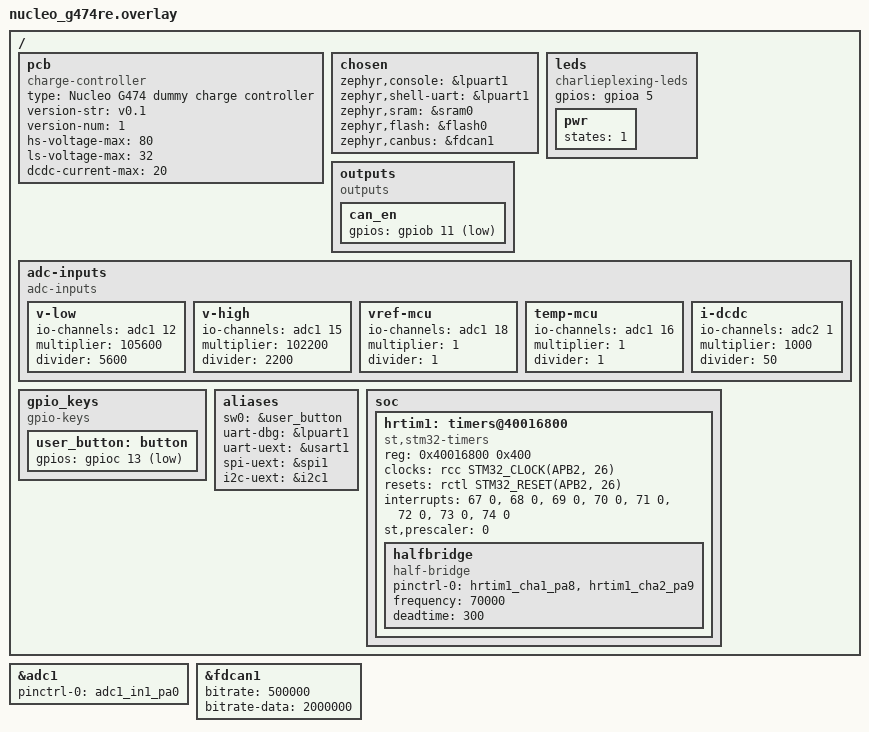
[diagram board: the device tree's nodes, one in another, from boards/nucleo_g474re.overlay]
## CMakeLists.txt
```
# Copyright (c) The Libre Solar Project Contributors
# SPDX-License-Identifier: Apache-2.0

cmake_minimum_required(VERSION 3.13.1)
find_package(Zephyr REQUIRED HINTS $ENV{ZEPHYR_BASE})

project(libre_solar_charge_controller)

add_subdirectory(src)

# determine git tag and commit hash for automatic firmware versioning
find_package(Git)
if(GIT_FOUND)
    execute_process(
        COMMAND ${GIT_EXECUTABLE} describe --long --dirty --tags
        OUTPUT_VARIABLE FIRMWARE_VERSION_ID
        OUTPUT_STRIP_TRAILING_WHITESPACE)
else()
    set(FIRMWARE_VERSION_ID "unknown")
endif()
add_definitions(-DFIRMWARE_VERSION_ID="${FIRMWARE_VERSION_ID}")
```

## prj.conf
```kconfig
# Main application configuration (overrides board-specific settings)

# only very small heap necessary for malloc in printf statements with %f
CONFIG_HEAP_MEM_POOL_SIZE=256

CONFIG_CPP=y
CONFIG_REQUIRES_FULL_LIBCPP=y

CONFIG_NEWLIB_LIBC=y
CONFIG_NEWLIB_LIBC_NANO=y
CONFIG_NEWLIB_LIBC_FLOAT_PRINTF=y

CONFIG_WATCHDOG=y
CONFIG_WDT_DISABLE_AT_BOOT=y
CONFIG_TASK_WDT=y
CONFIG_THREAD_NAME=y

CONFIG_REBOOT=y

CONFIG_HWINFO=y

CONFIG_CRC=y

CONFIG_CONSOLE_SUBSYS=y
CONFIG_CONSOLE_GETCHAR=y

# Use minimal logging by default to save memory for STM32F0 with little RAM
CONFIG_LOG=y
CONFIG_LOG_MODE_MINIMAL=y

CONFIG_THINGSET=y
CONFIG_THINGSET_SDK=y
CONFIG_THINGSET_STORAGE=y
CONFIG_THINGSET_SERIAL=y
CONFIG_THINGSET_STORAGE_DATA_VERSION=6
CONFIG_THINGSET_NODE_NAME="Libre Solar MPPT"

# Must be lower than LED thread to avoid flickering in boards with charlieplexing
CONFIG_THINGSET_SDK_THREAD_PRIORITY=6

# Uncomment to disable regular data publication on ThingSet serial at startup
#CONFIG_THINGSET_REPORTING_LIVE_ENABLE_PRESET=n

# Uncomment to enable I2C OLED display in UEXT connector
#CONFIG_UEXT_OLED_DISPLAY=y

# Select initial battery configuration: GEL (default), FLOODED, AGM, LFP, NMC or NMC_HV
#CONFIG_BAT_TYPE_???=y

# Change number of cells considering selected type (12V/24V battery by default if not set)
#CONFIG_BAT_NUM_CELLS=?
```

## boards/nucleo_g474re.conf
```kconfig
# SPDX-License-Identifier: Apache-2.0

CONFIG_FLASH=y
CONFIG_FLASH_PAGE_LAYOUT=y
CONFIG_FLASH_LOG_LEVEL_WRN=y

CONFIG_NVS=y
CONFIG_NVS_LOG_LEVEL_WRN=y
```

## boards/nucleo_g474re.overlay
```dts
/*
 * Copyright (c) The Libre Solar Project Contributors
 *
 * SPDX-License-Identifier: Apache-2.0
 *
 * This is a dummy charge controller board for testing new features using the STM32G474 MCU
 *
 * IMPORTANT: You have to remove the VREF jumper on the Nucleo board to make it work. Otherwise
 *            the MCU will get stuck while trying to generate a reference voltage at VREF+ pin.
 */

/ {
	/* delete conflicting nodes from Zephyr board */
	/delete-node/ leds;
	/delete-node/ aliases;

	pcb {
		compatible = "charge-controller";

		type = "Nucleo G474 dummy charge controller";
		version-str = "v0.1";
		version-num = <1>;

		hs-voltage-max = <80>;
		ls-voltage-max = <32>;
		dcdc-current-max = <20>;
	};

	chosen {
		zephyr,console = &lpuart1;
		zephyr,shell-uart = &lpuart1;
		zephyr,sram = &sram0;
		zephyr,flash = &flash0;
		zephyr,canbus = &fdcan1;
	};

	leds {
		compatible = "charlieplexing-leds";
		gpios = <&gpioa 5 GPIO_ACTIVE_HIGH>;

		pwr {
			states = <1>;
		};
	};

	outputs {
		compatible = "outputs";

		can_en {
			gpios = <&gpiob 11 GPIO_ACTIVE_LOW>;
		};
	};

	adc-inputs {
		compatible = "adc-inputs";

		v-low {
			io-channels = <&adc1 12>;
			multiplier = <105600>;
			divider = <5600>;
		};

		v-high {
			io-channels = <&adc1 15>;
			multiplier = <102200>;
			divider = <2200>;
		};

		vref-mcu {
			io-channels = <&adc1 18>;
			multiplier = <1>;
			divider = <1>;
		};

		temp-mcu {
			io-channels = <&adc1 16>;
			multiplier = <1>;
			divider = <1>;
		};

		i-dcdc {
			io-channels = <&adc2 1>;
			// amp gain: 25, resistor: 2 mOhm
			multiplier = <1000>;	// 1000
			divider = <50>;	// 2*25
		};
	};

	gpio_keys {
		compatible = "gpio-keys";
		user_button: button {
			gpios = <&gpioc 13 GPIO_ACTIVE_LOW>;
		};
	};

	aliases {
		sw0 = &user_button;
		uart-dbg = &lpuart1;
		uart-uext = &usart1;
		spi-uext = &spi1;
		i2c-uext = &i2c1;
	};

	soc {
		hrtim1: timers@40016800 {
			compatible = "st,stm32-timers";
			reg = <0x40016800 0x400>;
			clocks = <&rcc STM32_CLOCK(APB2, 26)>;
			resets = <&rctl STM32_RESET(APB2, 26)>;
			interrupts = <67 0>, <68 0>, <69 0>, <70 0>,
				     <71 0>, <72 0>, <73 0>, <74 0>;
			interrupt-names = "master", "tima", "timb", "timc",
					  "timd", "time", "flt", "timf";
			st,prescaler = <0>;
			status = "disabled";
		};
	};
};

&hrtim1 {
	status = "okay";

	halfbridge: halfbridge {
		compatible = "half-bridge";
		pinctrl-0 = <&hrtim1_cha1_pa8 &hrtim1_cha2_pa9>;
		pinctrl-names = "default";
		frequency = <70000>;
		deadtime = <300>;
	};
};

/*
// alternative to HRTIM
&timers1 {
	status = "okay";

	halfbridge: halfbridge {
		compatible = "half-bridge";
		pinctrl-0 = <&tim1_ch1_pa8 &tim1_ch1n_pb13>;
		pinctrl-names = "default";
		frequency = <70000>;
		deadtime = <300>;
	};
};
*/

&adc1 {
	pinctrl-0 = <&adc1_in1_pa0>;
	pinctrl-names = "default";
	status = "okay";
};

&fdcan1 {
	bitrate = <500000>;
	bitrate-data = <2000000>;
	status = "okay";
};
```

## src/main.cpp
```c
/*
 * Copyright (c) The Libre Solar Project Contributors
 *
 * SPDX-License-Identifier: Apache-2.0
 */

#ifndef UNIT_TEST

#include <stdio.h>
#include <zephyr/device.h>
#include <zephyr/drivers/gpio.h>
#include <zephyr/kernel.h>
#include <zephyr/task_wdt/task_wdt.h>

#include "helper.h"
#include "setup.h"

#include "bat_charger.h"   // battery settings and charger state machine
#include "daq.h"           // ADC using DMA and conversion to measurement values
#include "data_objects.h"  // for access to internal data via ThingSet
#include "dcdc.h"          // DC/DC converter control (hardware independent)
#include "device_status.h" // log data (error memory, min/max measurements, etc.)
#include "half_bridge.h"   // PWM generation for DC/DC converter
#include "hardware.h" // hardware-related functions like load switch, LED control, watchdog, etc.
#include "leds.h"     // LED switching using charlieplexing
#include "load.h"     // load and USB output management
#if BOARD_HAS_PWM_PORT
#include "pwm_switch.h" // PWM charge controller
#endif

int main(void)
{
    printf("Hardware: Libre Solar %s (%s)\n", DT_PROP(DT_PATH(pcb), type),
           DT_PROP(DT_PATH(pcb), version_str));
    printf("Firmware: %s\n", FIRMWARE_VERSION_ID);

    task_wdt_init(DEVICE_DT_GET_OR_NULL(DT_NODELABEL(iwdg)));

    setup();

    battery_conf_init(&bat_conf, CONFIG_BAT_TYPE, CONFIG_BAT_NUM_CELLS, CONFIG_BAT_CAPACITY_AH);
    battery_conf_overwrite(&bat_conf, &bat_conf_user); // initialize conf_user with same values

#if BOARD_HAS_DCDC
    daq_set_hv_limit(DT_PROP(DT_PATH(pcb), hs_voltage_max));
#endif

#if CONFIG_HV_TERMINAL_SOLAR || CONFIG_LV_TERMINAL_SOLAR || CONFIG_PWM_TERMINAL_SOLAR
    solar_terminal.init_solar();
#endif

#if CONFIG_HV_TERMINAL_NANOGRID
    grid_terminal.init_nanogrid();
#endif

    // make sure loaded configuration is valid
    data_objects_init();

    // Data Acquisition (DAQ) setup
    daq_setup();

    charger.detect_num_batteries(&bat_conf); // check if we have 24V instead of 12V system
    charger.init_terminal(&bat_conf);

#if BOARD_HAS_LOAD_OUTPUT
    load.set_voltage_limits(bat_conf.load_disconnect_voltage, bat_conf.load_reconnect_voltage,
                            bat_conf.absolute_max_voltage);
#endif

#if BOARD_HAS_USB_OUTPUT
    usb_pwr.set_voltage_limits(bat_conf.load_disconnect_voltage - 0.1f, // keep on longer than load
                               bat_conf.load_reconnect_voltage, bat_conf.absolute_max_voltage);
#endif

    // wait until all threads are spawned before activating the watchdog
    k_sleep(K_MSEC(2500));

    int64_t t_start = k_uptime_get();

    while (true) {
        // loop runs exactly once per second and includes slow control tasks and energy calculation

        charger.discharge_control(&bat_conf);
        charger.charge_control(&bat_conf);

// energy + soc calculation must be called exactly once per second
#if BOARD_HAS_DCDC
        if (dcdc.state != DCDC_CONTROL_OFF) {
            hv_terminal.energy_balance();
        }
#endif

#if BOARD_HAS_PWM_PORT
        if (pwm_switch.active() == 1) {
            pwm_switch.energy_balance();
        }
#endif

        lv_terminal.energy_balance();

#if BOARD_HAS_LOAD_OUTPUT
        if (load.state == 1) {
            load.energy_balance();
        }
#endif

        dev_stat.update_energy();
        dev_stat.update_min_max_values();
        charger.update_soc(&bat_conf);

#if CONFIG_HS_MOSFET_FAIL_SAFE_PROTECTION && BOARD_HAS_DCDC
        if (dev_stat.has_error(ERR_DCDC_HS_MOSFET_SHORT)) {
            dcdc.fuse_destruction();
        }
#endif

        leds_update_1s();

#if BOARD_HAS_LOAD_OUTPUT
        leds_update_soc(charger.soc, flags_check(&load.error_flags, ERR_LOAD_SHEDDING));
#else
        leds_update_soc(charger.soc, false);
#endif

        t_start += 1000;
        k_sleep(K_TIMEOUT_ABS_MS(t_start));
    }
}

void control_thread()
{
    int wdt_channel = task_wdt_add(200, task_wdt_callback, (void *)k_current_get());

    while (true) {
        // control loop runs at approx. 10 Hz

        bool charging = false;

        task_wdt_feed(wdt_channel);

        // convert ADC readings to meaningful measurement values
        daq_update();

        // alerts should trigger only for transients, so update based on actual voltage
        daq_set_lv_limits(lv_terminal.bus->voltage * 1.2F, lv_terminal.bus->voltage * 0.8F);

        lv_terminal.update_bus_current_margins();

#if BOARD_HAS_PWM_PORT
        pwm_switch.control();
        charging |= pwm_switch.active();
#endif

#if BOARD_HAS_DCDC
        hv_terminal.update_bus_current_margins();
        dcdc.control(); // control of DC/DC including MPPT algorithm
        charging |= half_bridge_enabled();
#endif

        leds_set_charging(charging);

#if BOARD_HAS_LOAD_OUTPUT
        load.control();
#endif

#if BOARD_HAS_USB_OUTPUT
        usb_pwr.control();
#endif

        k_sleep(K_MSEC(100));
    }
}

// 2s delay for control thread as a safety feature: be able to re-flash before starting
// priority is set to -1 (=cooperative) to have higher priority than other threads incl. main
K_THREAD_DEFINE(control_thread_id, 1024, control_thread, NULL, NULL, NULL, -1, 0, 2000);

#endif // UNIT_TEST
```

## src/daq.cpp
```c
/*
 * Copyright (c) The Libre Solar Project Contributors
 *
 * SPDX-License-Identifier: Apache-2.0
 */

#include "daq.h"

#include <zephyr/kernel.h>

#include <zephyr/logging/log.h>
LOG_MODULE_REGISTER(daq, CONFIG_DAQ_LOG_LEVEL);

#include <assert.h>
#include <math.h> // log for thermistor calculation

#include "mcu.h"
#include "setup.h"

// typical value for Semitec 103AT-5 thermistor: 3435
#define NTC_BETA_VALUE 3435

// filter parameter c for additional battery voltage and current low-pass filter
// c = dt / (tau + dt) = 0.1s / (10s + 0.1s)
#define HV_BUS_VOLTAGE_FILTER_CONST      0.0099F
#define LV_BUS_VOLTAGE_FILTER_CONST      0.0099F
#define LV_TERMINAL_CURRENT_FILTER_CONST 0.0099F
#define PWM_CURRENT_FILTER_CONST         0.0625F // 1.5 seconds

#if BOARD_HAS_DCDC
static uint16_t dcdc_current_offset_raw;
#endif
#if BOARD_HAS_PWM_PORT
static uint16_t pwm_current_offset_raw;
#endif
#if BOARD_HAS_LOAD_OUTPUT
static uint16_t load_current_offset_raw;
#endif

// 16-bit ADC raw readings (actually left-aligned 12-bit, i.e. left-shifted by 4 bits)
volatile uint16_t adc_readings[NUM_ADC_CH] = {};

// filtered raw readings left-shifted by additional adc_filter_const[channel] bits
volatile uint32_t adc_filtered[NUM_ADC_CH] = {};

static volatile AdcAlert adc_alerts_upper[NUM_ADC_CH] = {};
static volatile AdcAlert adc_alerts_lower[NUM_ADC_CH] = {};

/*
 * Channel-specific ADC filter constant from devicetree
 *
 * multiplier = 1/(2^adc_filter_const[channel])
 */
#define ADC_FILTER_CONST(node_id) DT_PROP(node_id, filter_const),
static const uint8_t adc_filter_const[NUM_ADC_CH] = { DT_FOREACH_CHILD(DT_PATH(adc_inputs),
                                                                       ADC_FILTER_CONST) };

/**
 * Average value for ADC channel
 *
 * @param channel valid ADC channel position using ADC_POS() macro
 */
static inline uint32_t adc_raw_filtered(uint32_t channel)
{
    return adc_filtered[channel] >> adc_filter_const[channel];
}

/**
 * Measured current/voltage for ADC channel after average and scaling
 *
 * @param channel valid ADC channel position using ADC_POS() macro
 * @param vref reference voltage in millivolts
 * @param offset offset added to raw ADC value before applying gain
 *
 * @return scaled final value in volts/amps
 */
static inline float adc_scaled(uint32_t channel, int32_t vref, const float gain, int32_t offset = 0)
{
    return adc_raw_to_voltage(adc_raw_filtered(channel) - offset, vref) * gain;
}

static inline float ntc_temp(uint32_t channel, int32_t vref, float ntc_series_resistor)
{
    /** \todo Improved (faster) temperature calculation:
       https://www.embeddedrelated.com/showarticle/91.php
    */

    // voltage read by ADC (mV)
    float v_temp = adc_raw_to_voltage(adc_raw_filtered(channel), vref) * 1000;

    // resistance of NTC (Ohm)
    float rts = ntc_series_resistor * v_temp / (vref - v_temp);

    return 1.0f / (1.0f / (273.15f + 25.0f) + 1.0f / (float)NTC_BETA_VALUE * logf(rts / 10000.0f))
           - 273.15f; // °C
}

void calibrate_current_sensors()
{
#if BOARD_HAS_DCDC
    dcdc_current_offset_raw = adc_raw_filtered(ADC_POS(i_dcdc));
#endif
#if BOARD_HAS_PWM_PORT
    pwm_current_offset_raw = adc_raw_filtered(ADC_POS(i_pwm));
#endif
#if BOARD_HAS_LOAD_OUTPUT
    load_current_offset_raw = adc_raw_filtered(ADC_POS(i_load));
#endif
}

void adc_update_value(unsigned int pos)
{
#if BOARD_HAS_PWM_PORT
    // only read input voltage and current when switch is on or permanently off
    if ((pos != ADC_POS(v_pwm) && pos != ADC_POS(i_pwm)) || pwm_switch.signal_high()
        || pwm_switch.active() == false)
#endif
    {
        /*
         * Low-pass filtering of ADC raw readings
         * (see also: http://techteach.no/simview/lowpass_filter/doc/filter_algorithm.pdf)
         *
         * y(n) = c * x(n) + (1 - c) * y(n-1) with filter constant c = 1/(2^adc_filter_const[pos])
         *
         * Remarks regarding below implementation optimized for efficiency:
         *
         * 1. adc_readings has different fixed-point math format, so that it would have to be
         *    aligned with << adc_filter_const[pos] before calculation. Not aligning it is
         *    equivalent to multiplication with c:
         *    adc_readings[pos] == c * (adc_readings[pos] << adc_filter_const[pos])
         *
         * 2. c * adc_filtered[pos] == adc_filtered[pos] >> adc_filter_const[pos]
         */
        adc_filtered[pos] = (uint32_t)adc_readings[pos] + adc_filtered[pos]
                            - (adc_filtered[pos] >> adc_filter_const[pos]);
    }

    // check upper alerts
    adc_alerts_upper[pos].debounce_ms++;
    if (adc_alerts_upper[pos].callback != NULL && adc_readings[pos] >= adc_alerts_upper[pos].limit)
    {
        if (adc_alerts_upper[pos].debounce_ms > 1) {
            // create function pointer and call function
            adc_alerts_upper[pos].callback();
        }
    }
    else if (adc_alerts_upper[pos].debounce_ms > 0) {
        // reset debounce ms counter only if already close to triggering to allow setting negative
        // values to specify a one-time inhibit delay
        adc_alerts_upper[pos].debounce_ms = 0;
    }

    // same for lower alerts
    adc_alerts_lower[pos].debounce_ms++;
    if (adc_alerts_lower[pos].callback != NULL && adc_readings[pos] <= adc_alerts_lower[pos].limit)
    {
        if (adc_alerts_lower[pos].debounce_ms > 1) {
            adc_alerts_lower[pos].callback();
        }
    }
    else if (adc_alerts_lower[pos].debounce_ms > 0) {
        adc_alerts_lower[pos].debounce_ms = 0;
    }
}

void daq_update()
{
    int vref = VREF;

    // calculate lower voltage first, as it is needed for PWM terminal voltage calculation
    lv_bus.voltage = adc_scaled(ADC_POS(v_low), vref, ADC_GAIN(v_low));

    if (lv_bus.voltage_filtered != 0.0F) {
        lv_bus.voltage_filtered = LV_BUS_VOLTAGE_FILTER_CONST * lv_bus.voltage
                                  + (1.0F - LV_BUS_VOLTAGE_FILTER_CONST) * lv_bus.voltage_filtered;
    }
    else {
        // initialize properly at startup
        lv_bus.voltage_filtered = lv_bus.voltage;
    }

#if BOARD_HAS_DCDC
    hv_bus.voltage = adc_scaled(ADC_POS(v_high), vref, ADC_GAIN(v_high));

    if (hv_bus.voltage_filtered != 0.0F) {
        hv_bus.voltage_filtered = HV_BUS_VOLTAGE_FILTER_CONST * hv_bus.voltage
                                  + (1.0F - HV_BUS_VOLTAGE_FILTER_CONST) * hv_bus.voltage_filtered;
    }
    else {
        // initialize properly at startup
        hv_bus.voltage_filtered = hv_bus.voltage;
    }
#endif

#if BOARD_HAS_PWM_PORT
    pwm_switch.ext_voltage =
        lv_bus.voltage - adc_scaled(ADC_POS(v_pwm), vref, ADC_GAIN(v_pwm), ADC_OFFSET(v_pwm));
#endif

#if BOARD_HAS_LOAD_OUTPUT
    load.current = adc_scaled(ADC_POS(i_load), vref, ADC_GAIN(i_load), load_current_offset_raw);
    float load_current = load.current;
#else
    float load_current = 0; // value used below, so we still need to define the variable
#endif

    float lv_terminal_current = -load_current;

#if BOARD_HAS_PWM_PORT
    // current multiplied with PWM duty cycle for PWM charger to get avg current for correct power
    // calculation
    pwm_switch.current =
        -pwm_switch.get_duty_cycle()
        * adc_scaled(ADC_POS(i_pwm), vref, ADC_GAIN(i_pwm), pwm_current_offset_raw);
    pwm_switch.current_filtered = PWM_CURRENT_FILTER_CONST * pwm_switch.current
                                  + (1.0F - PWM_CURRENT_FILTER_CONST) * pwm_switch.current_filtered;

    lv_terminal_current -= pwm_switch.current;

    pwm_switch.power = pwm_switch.bus->voltage * pwm_switch.current;
#endif

#if BOARD_HAS_DCDC
    dcdc.inductor_current =
        adc_scaled(ADC_POS(i_dcdc), vref, ADC_GAIN(i_dcdc), dcdc_current_offset_raw);

    lv_terminal_current += dcdc.inductor_current;

    hv_terminal.current =
        -dcdc.inductor_current * lv_terminal.bus->voltage / hv_terminal.bus->voltage;

    dcdc.power = dcdc.lvb->voltage * dcdc.inductor_current;
    hv_terminal.power = hv_terminal.bus->voltage * hv_terminal.current;
#endif
    lv_terminal.current = lv_terminal_current;
    lv_terminal.power = lv_terminal.bus->voltage * lv_terminal.current;

    lv_terminal.current_filtered =
        LV_TERMINAL_CURRENT_FILTER_CONST * lv_terminal.current
        + (1.0F - LV_TERMINAL_CURRENT_FILTER_CONST) * lv_terminal.current_filtered;

#if BOARD_HAS_LOAD_OUTPUT
    load.power = load.bus->voltage * load.current;
#endif

#if BOARD_HAS_TEMP_BAT
    // battery temperature calculation
    float bat_temp = ntc_temp(ADC_POS(temp_bat), vref, ADC_GAIN(temp_bat));

    if (bat_temp > -50) {
        // external sensor connected: take measured value
        charger.bat_temperature = bat_temp;
        charger.ext_temp_sensor = true;
    }
    else {
        // no external sensor: assume typical room temperature
        charger.bat_temperature = 25;
        charger.ext_temp_sensor = false;
    }
#endif

#if BOARD_HAS_TEMP_FETS
    dcdc.temp_mosfets = ntc_temp(ADC_POS(temp_fets), vref, ADC_GAIN(temp_fets));
#endif

    // internal MCU temperature (calibrated using 12-bit right-aligned readings)
    uint16_t adcval = (adc_raw_filtered(ADC_POS(temp_mcu)) >> 4) * vref / VREFINT_VALUE;
    dev_stat.internal_temp = (TSENSE_CAL2_VALUE - TSENSE_CAL1_VALUE) / (TSENSE_CAL2 - TSENSE_CAL1)
                                 * (adcval - TSENSE_CAL1)
                             + TSENSE_CAL1_VALUE;

    if (dev_stat.internal_temp > 80) {
        dev_stat.set_error(ERR_INT_OVERTEMP);
    }
    else if (dev_stat.internal_temp < 70 && (dev_stat.has_error(ERR_INT_OVERTEMP))) {
        // remove error flag with hysteresis of 10°C
        dev_stat.clear_error(ERR_INT_OVERTEMP);
    }
    // else: keep previous setting
}

void lv_overvoltage_alert()
{
    // disable any sort of input
#if BOARD_HAS_DCDC
    dcdc.stop();
#endif
#if BOARD_HAS_PWM_PORT
    pwm_switch.stop();
#endif
    // do not use enter_state function, as we don't want to wait entire recharge delay
    charger.state = CHG_STATE_IDLE;

    dev_stat.set_error(ERR_BAT_OVERVOLTAGE);

    LOG_ERR("Low-side overvoltage alert, ADC reading: %d limit: %d\n", adc_readings[ADC_POS(v_low)],
            adc_alerts_upper[ADC_POS(v_low)].limit);
}

void lv_undervoltage_alert()
{
#if BOARD_HAS_LOAD_OUTPUT
    // the battery undervoltage must have been caused by a load current peak
    load.stop(ERR_LOAD_VOLTAGE_DIP);
#endif

    LOG_ERR("Low-side undervoltage alert, ADC reading: %d limit: %d\n",
            adc_readings[ADC_POS(v_low)], adc_alerts_lower[ADC_POS(v_low)].limit);
}

#if BOARD_HAS_DCDC
void hv_overvoltage_alert()
{
    dcdc.stop();

    // do not use enter_state function, as we don't want to wait entire recharge delay
    charger.state = CHG_STATE_IDLE;

    dev_stat.set_error(ERR_DCDC_HS_OVERVOLTAGE);

    LOG_ERR("High-side overvoltage alert, ADC reading: %d limit: %d\n",
            adc_readings[ADC_POS(v_high)], adc_alerts_upper[ADC_POS(v_high)].limit);
}
#endif

void adc_upper_alert_inhibit(int adc_pos, int timeout_ms)
{
    // set negative value so that we get a final debouncing of this timeout + the original
    // delay in the alert function (currently only waiting for 2 samples = 2 ms)
    adc_alerts_upper[adc_pos].debounce_ms = -timeout_ms;
}

uint16_t adc_raw_clamp(float scale, float limit)
{
    // even if we have a higher voltage limit, we must limit it
    // to the max value the ADC will be able to deliver
    const float limit_scaled = limit * scale;
    return limit_scaled > (float)UINT16_MAX ? UINT16_MAX : (uint16_t)(limit_scaled);
}

void daq_set_lv_limits(float lv_overvoltage, float lv_undervoltage)
{
    float scale = (((4096 << 4) * 1000) / ADC_GAIN(v_low)) / (float)VREF;

    // LV side (battery) overvoltage alert
    adc_alerts_upper[ADC_POS(v_low)].limit = adc_raw_clamp(scale, lv_overvoltage);
    adc_alerts_upper[ADC_POS(v_low)].callback = lv_overvoltage_alert;

    // LV side (battery) undervoltage alert
    adc_alerts_lower[ADC_POS(v_low)].limit = adc_raw_clamp(scale, lv_undervoltage);
    adc_alerts_lower[ADC_POS(v_low)].callback = lv_undervoltage_alert;
}

#if BOARD_HAS_DCDC
void daq_set_hv_limit(float hv_overvoltage)
{
    float scale = (((4096 << 4) * 1000) / ADC_GAIN(v_high)) / (float)VREF;

    // HV side (solar/grid) overvoltage alert
    adc_alerts_upper[ADC_POS(v_high)].limit = adc_raw_clamp(scale, hv_overvoltage);
    adc_alerts_upper[ADC_POS(v_high)].callback = hv_overvoltage_alert;
}
#endif

#if !defined(CONFIG_SOC_FAMILY_STM32)

#include "daq_stub.h"

void prepare_adc_readings(AdcValues values)
{
    adc_readings[ADC_POS(vref_mcu)] = (uint16_t)(1.224 / 3.3 * 4096) << 4;
    adc_readings[ADC_POS(v_high)] =
        (uint16_t)((values.solar_voltage / ADC_GAIN(v_high)) / 3.3f * 4096) << 4;
    adc_readings[ADC_POS(v_low)] =
        (uint16_t)((values.battery_voltage / ADC_GAIN(v_low)) / 3.3f * 4096) << 4;
    adc_readings[ADC_POS(i_dcdc)] =
        (uint16_t)((values.dcdc_current / ADC_GAIN(i_dcdc)) / 3.3f * 4096) << 4;
    adc_readings[ADC_POS(i_load)] =
        (uint16_t)((values.load_current / ADC_GAIN(i_load)) / 3.3f * 4096) << 4;
}

void prepare_adc_filtered()
{
    // initialize also filtered values
    for (int i = 0; i < NUM_ADC_CH; i++) {
        adc_filtered[i] = adc_readings[i] << adc_filter_const[i];
    }
}

void clear_adc_filtered()
{
    // initialize also filtered values
    for (int i = 0; i < NUM_ADC_CH; i++) {
        adc_filtered[i] = 0;
    }
}
uint32_t get_adc_filtered(uint32_t channel)
{
    return adc_raw_filtered(channel);
}

#endif /* UNIT_TEST */
```

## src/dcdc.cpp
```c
/*
 * Copyright (c) The Libre Solar Project Contributors
 *
 * SPDX-License-Identifier: Apache-2.0
 */

#include "dcdc.h"

#include <zephyr/kernel.h>

#include <zephyr/device.h>
#include <zephyr/drivers/gpio.h>

#include <math.h> // for fabs function
#include <stdio.h>
#include <stdlib.h> // for min/max function

#include "device_status.h"
#include "half_bridge.h"
#include "helper.h"
#include "setup.h"

#include <thingset.h>
#include <thingset/sdk.h>
#include <thingset/storage.h>

LOG_MODULE_REGISTER(dcdc, CONFIG_DCDC_LOG_LEVEL);

#if BOARD_HAS_DCDC

#define BUCK_DUTY_POWER_DECREASE (-1)
#define BUCK_DUTY_POWER_INCREASE (1)

#define BOOST_DUTY_POWER_DECREASE (1)
#define BOOST_DUTY_POWER_INCREASE (-1)

#ifdef CONFIG_SOC_SERIES_STM32G4X
#define DUTY_STEP_SIZE (3) // increased step size for fast microcontroller
#else
#define DUTY_STEP_SIZE (1) // single minimum step for other microcontrollers
#endif

#if DT_NODE_EXISTS(DT_CHILD(DT_PATH(outputs), hv_out))
#define HV_OUT_NODE DT_CHILD(DT_PATH(outputs), hv_out)
#endif

extern DeviceStatus dev_stat;

Dcdc::Dcdc(DcBus *high, DcBus *low, DcdcOperationMode op_mode)
{
    hvb = high;
    lvb = low;
    mode = op_mode;
    enable = true;
    state = DCDC_CONTROL_OFF;
    inductor_current_max = DT_PROP(DT_PATH(pcb), dcdc_current_max);
    hs_voltage_max = DT_PROP(DT_PATH(pcb), hs_voltage_max);
    ls_voltage_max = DT_PROP(DT_PATH(pcb), ls_voltage_max);
    ls_voltage_min = 9.0;
    output_power_min = 1; // switch off if power < 1 W
    restart_interval = 60;
    off_timestamp = -10000; // start immediately

    // lower duty limit might have to be adjusted dynamically depending on LS voltage
    half_bridge_init(DT_PROP(DT_INST(0, half_bridge), frequency) / 1000,
                     DT_PROP(DT_INST(0, half_bridge), deadtime), 12 / hs_voltage_max, 0.97);
}

void Dcdc::perturb_observe_buck()
{
    if (power >= output_power_min) {
        power_good_timestamp = uptime();
    }

    if ((uptime() - power_good_timestamp > 10 || power < -10.0f) && mode != DCDC_MODE_AUTO) {
        // switch off after 10s low power or negative power (if not in nanogrid mode)
        pwm_direction = 0;
    }
    else if (lvb->voltage > lvb->sink_control_voltage()) {
        state = DCDC_CONTROL_CV_LS;
        pwm_direction = BUCK_DUTY_POWER_DECREASE;
    }
    else if (lvb->sink_current_margin < 0 || inductor_current > inductor_current_max) {
        state = DCDC_CONTROL_CC_LS;
        pwm_direction = BUCK_DUTY_POWER_DECREASE;
    }
    else if (hvb->src_current_margin > 0) {
        state = DCDC_CONTROL_CC_HS;
        pwm_direction = BUCK_DUTY_POWER_DECREASE;
    }
    else if (hvb->voltage < hvb->src_control_voltage() && power > output_power_min) {
        // input voltage below limit
        state = DCDC_CONTROL_CV_HS;
        pwm_direction = BUCK_DUTY_POWER_DECREASE;
    }
    else if (temp_mosfets > DCDC_MOSFETS_MAX_TEMP) {
        state = DCDC_CONTROL_DERATING;
        pwm_direction = BUCK_DUTY_POWER_DECREASE;
    }
    else if (power < output_power_min && lvb->voltage < lvb->src_control_voltage()) {
        // no load condition (e.g. start-up of nanogrid) --> raise voltage
        pwm_direction = BUCK_DUTY_POWER_INCREASE;
    }
    else {
        state = DCDC_CONTROL_MPPT;
        if (power_prev > power) {
            pwm_direction = -pwm_direction;
        }
    }

    power_prev = power;
}

void Dcdc::perturb_observe_boost()
{
    if (-power >= output_power_min) {
        power_good_timestamp = uptime();
    }

    if ((uptime() - power_good_timestamp > 10 || -power < -10.0f) && mode != DCDC_MODE_AUTO) {
        // switch off after 10s low power or negative power (if not in nanogrid mode)
        pwm_direction = 0;
    }
    else if (hvb->voltage > hvb->sink_control_voltage()) {
        state = DCDC_CONTROL_CV_HS;
        pwm_direction = BOOST_DUTY_POWER_DECREASE;
    }
    else if (hvb->sink_current_margin < 0) {
        state = DCDC_CONTROL_CC_HS;
        pwm_direction = BOOST_DUTY_POWER_DECREASE;
    }
    else if (lvb->src_current_margin > 0 || -inductor_current > inductor_current_max) {
        state = DCDC_CONTROL_CC_LS;
        pwm_direction = BOOST_DUTY_POWER_DECREASE;
    }
    else if (lvb->voltage < lvb->src_control_voltage() && -power > output_power_min) {
        // input voltage below limit
        state = DCDC_CONTROL_CV_LS;
        pwm_direction = BOOST_DUTY_POWER_DECREASE;
    }
    else if (temp_mosfets > DCDC_MOSFETS_MAX_TEMP) {
        state = DCDC_CONTROL_DERATING;
        pwm_direction = BOOST_DUTY_POWER_DECREASE;
    }
    else if (-power < output_power_min && hvb->voltage < hvb->src_control_voltage()) {
        // no load condition (e.g. start-up of nanogrid) --> raise voltage
        pwm_direction = BOOST_DUTY_POWER_INCREASE;
    }
    else {
        state = DCDC_CONTROL_MPPT;
        if (-power_prev > -power) {
            pwm_direction = -pwm_direction;
        }
    }

    power_prev = power;
}

__weak DcdcOperationMode Dcdc::check_start_conditions()
{
    if (enable == false
        || hvb->voltage > hs_voltage_max // also critical for buck mode because of ringing
        || lvb->voltage > ls_voltage_max || lvb->voltage < ls_voltage_min
        || dev_stat.has_error(ERR_BAT_UNDERVOLTAGE | ERR_BAT_OVERVOLTAGE)
        || (int)uptime() < (off_timestamp + (int)restart_interval))
    {
        return DCDC_MODE_OFF;
    }

    if (lvb->sink_current_margin > 0 && lvb->voltage < lvb->sink_control_voltage()
        && hvb->src_current_margin < 0 && hvb->voltage > hvb->src_control_voltage()
        && hvb->voltage * 0.85f > lvb->voltage)
    {
        return DCDC_MODE_BUCK;
    }

    if (hvb->sink_current_margin > 0 && hvb->voltage < hvb->sink_control_voltage()
        && lvb->src_current_margin < 0 && lvb->voltage > lvb->src_control_voltage())
    {
        return DCDC_MODE_BOOST;
    }

    return DCDC_MODE_OFF;
}

bool Dcdc::check_hs_mosfet_short()
{
    static uint32_t first_time_detected;
    if (half_bridge_enabled() == false && inductor_current > 0.5F
        && lvb->voltage_filtered > lvb->sink_control_voltage())
    {
        // if there is current even though the DC/DC is switched off, the
        // high-side MOSFET must be broken --> set flag and let main() decide
        // what to do... (e.g. call dcdc_self_destruction)

        uint32_t now = uptime();
        if (first_time_detected == 0) {
            first_time_detected = now;
        }
        else if (now - first_time_detected > 10) {
            // waited approx 10s before setting the flag
            dev_stat.set_error(ERR_DCDC_HS_MOSFET_SHORT);
        }
    }
    else {
        first_time_detected = 0;
    }

    return dev_stat.has_error(ERR_DCDC_HS_MOSFET_SHORT);
}

bool Dcdc::startup_inhibit(bool reset)
{
    static uint32_t inhibit_start;

    if (reset) {
        inhibit_start = uptime();
        return true;
    }
    else {
        return (uptime() < inhibit_start + DCDC_STARTUP_INHIBIT_TIME);
    }
}

__weak void Dcdc::control()
{
    if (half_bridge_enabled() == false) {

        if (check_hs_mosfet_short()) {
            return;
        }

        int startup_mode = check_start_conditions();

        if ((startup_mode == DCDC_MODE_BUCK && mode == DCDC_MODE_BUCK)
            || (startup_mode == DCDC_MODE_BOOST && mode == DCDC_MODE_BOOST)
            || (startup_mode != DCDC_MODE_OFF && mode == DCDC_MODE_AUTO))
        {
            output_hvs_enable();

            // startup allowed, but we need to wait until voltages settle
            if (startup_inhibit()) {
                return;
            }

            const char *mode_name = NULL;
            if (startup_mode == DCDC_MODE_BUCK) {
                mode_name = "buck";
                pwm_direction = BUCK_DUTY_POWER_INCREASE;
                // Don't start directly at Vmpp (approx. 0.8 * Voc) to prevent high inrush
                // currents and stress on MOSFETs
                half_bridge_set_duty_cycle(lvb->voltage / (hvb->voltage - 1));
            }
            else {
                mode_name = "boost";
                pwm_direction = BOOST_DUTY_POWER_INCREASE;
                // Will automatically start with max. duty (0.97) if connected to a
                // nanogrid not yet started up (zero voltage)
                half_bridge_set_duty_cycle(lvb->voltage / (hvb->voltage + 1));
            }

            half_bridge_start();
            power_good_timestamp = uptime();
            printf("DC/DC %s mode start (HV: %.2fV, LV: %.2fV, PWM: %.1f).\n", mode_name,
                   (double)hvb->voltage, (double)lvb->voltage,
                   (double)half_bridge_get_duty_cycle() * 100.0);
        }
        else {
            startup_inhibit(true); // reset inhibit counter
        }
    }
    else { // half bridge is on

        const char *stop_reason = NULL;
        if (lvb->voltage > ls_voltage_max || hvb->voltage > hs_voltage_max) {
            stop_reason = "emergency (voltage limits exceeded)";
        }
        else if (enable == false) {
            stop_reason = "disabled";
        }
        else {
            if (mode == DCDC_MODE_BUCK || (mode == DCDC_MODE_AUTO && inductor_current > 0.1f)) {
                perturb_observe_buck();
            }
            else {
                perturb_observe_boost();
            }

            if (pwm_direction != 0) {
                half_bridge_set_ccr(half_bridge_get_ccr() + pwm_direction * DUTY_STEP_SIZE);

                // requires floating point support with CONFIG_CBPRINTF_FP_SUPPORT=y
                LOG_DBG("P %.2fW, inductor %.2fA, HS: %.2fV, %.2fA margin, "
                        "LS: %.2fV (target %.2fV), %.2fA margin, "
                        "PWM: %.1f, dcdc_state: %d, pwm_direction: %d",
                        (double)power, (double)inductor_current, (double)hvb->voltage,
                        (double)hvb->src_current_margin, (double)lvb->voltage,
                        (double)lvb->sink_voltage_intercept, (double)lvb->sink_current_margin,
                        (double)half_bridge_get_duty_cycle() * 100.0, state, pwm_direction);
            }
            else {
                stop_reason = "low power";
            }
        }

        if (stop_reason != NULL) {
            stop();
            printf("DC/DC Stop: %s.\n", stop_reason);
        }
    }
}

void Dcdc::test()
{
    if (half_bridge_enabled()) {
        const char *stop_reason = NULL;
        if (lvb->voltage > ls_voltage_max || hvb->voltage > hs_voltage_max) {
            stop_reason = "emergency (voltage limits exceeded)";
        }
        else if (enable == false) {
            stop_reason = "disabled";
        }
        else {
            if (half_bridge_get_duty_cycle() > 0.50f) {
                half_bridge_set_ccr(half_bridge_get_ccr() - 1);
            }
            else {
                half_bridge_set_ccr(half_bridge_get_ccr() + 1);
            }
        }
        if (stop_reason != NULL) {
            stop();
            printf("DC/DC Stop: %s.\n", stop_reason);
        }
    }
    else {
        if (check_start_conditions() != DCDC_MODE_OFF) {
            // startup allowed, but we need to wait until voltages settle
            if (startup_inhibit()) {
                return;
            }

            half_bridge_set_duty_cycle(lvb->voltage / hvb->voltage);
            half_bridge_start();
            printf("DC/DC test mode start (HV: %.2fV, LV: %.2fV, PWM: %.1f).\n",
                   (double)hvb->voltage, (double)lvb->voltage,
                   (double)half_bridge_get_duty_cycle() * 100.0);
        }
        else {
            startup_inhibit(true); // reset inhibit counter
        }
    }
}

void Dcdc::stop()
{
    half_bridge_stop();
    state = DCDC_CONTROL_OFF;
    off_timestamp = uptime();
    output_hvs_disable();
}

void Dcdc::fuse_destruction()
{
    static int counter = 0;

    if (counter > 20) { // wait 20s to be able to send out data
        LOG_ERR("Charge controller fuse destruction called!\n");
        thingset_storage_save();
        half_bridge_stop();
        half_bridge_init(50, 0, 0, 0.98); // reset safety limits to allow 0% duty cycle
        half_bridge_set_duty_cycle(0);
        half_bridge_start();
        // now the fuse should be triggered and we disappear
    }
    counter++;
}

void Dcdc::output_hvs_enable()
{
#ifdef HV_OUT_NODE
    const struct device *hv_out = DEVICE_DT_GET(DT_GPIO_CTLR(HV_OUT_NODE, gpios));
    if (device_is_ready(hv_out)) {
        gpio_pin_configure(hv_out, DT_GPIO_PIN(HV_OUT_NODE, gpios),
                           DT_GPIO_FLAGS(HV_OUT_NODE, gpios) | GPIO_OUTPUT_ACTIVE);
    }
#endif
}

void Dcdc::output_hvs_disable()
{
#ifdef HV_OUT_NODE
    const struct device *hv_out = DEVICE_DT_GET(DT_GPIO_CTLR(HV_OUT_NODE, gpios));
    if (device_is_ready(hv_out)) {
        gpio_pin_configure(hv_out, DT_GPIO_PIN(HV_OUT_NODE, gpios),
                           DT_GPIO_FLAGS(HV_OUT_NODE, gpios) | GPIO_OUTPUT_INACTIVE);
    }
#endif
}

#else

Dcdc::Dcdc(DcBus *high, DcBus *low, DcdcOperationMode op_mode)
{}

#endif /* BOARD_HAS_DCDC */
```

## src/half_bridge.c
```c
/*
 * Copyright (c) The Libre Solar Project Contributors
 *
 * SPDX-License-Identifier: Apache-2.0
 */

#define DT_DRV_COMPAT half_bridge

#include "half_bridge.h"

#include <zephyr/kernel.h>

#include <stdio.h>

#include "board.h"
#include "mcu.h"

#ifdef CONFIG_SOC_FAMILY_STM32
#include <soc.h>
#include <stm32_ll_bus.h>
#include <zephyr/drivers/pinctrl.h>
#endif

#if BOARD_HAS_DCDC

// Get address of used timer from board dts
#define TIMER_ADDR DT_REG_ADDR(DT_PARENT(DT_DRV_INST(0)))

static uint16_t tim_ccr_min; // capture/compare register min/max
static uint16_t tim_ccr_max;
static uint16_t tim_dt_clocks = 0;

static uint16_t clamp_ccr(uint16_t ccr_target)
{
    // protection against wrong settings which could destroy the hardware
    if (ccr_target <= tim_ccr_min) {
        return tim_ccr_min;
    }
    else if (ccr_target >= tim_ccr_max) {
        return tim_ccr_max;
    }
    else {
        return ccr_target;
    }
}

#ifdef CONFIG_SOC_FAMILY_STM32

#define PINCTRL_NODE DT_NODELABEL(halfbridge)

PINCTRL_DT_DEFINE(PINCTRL_NODE);

static const struct pinctrl_dev_config *pincfg = PINCTRL_DT_DEV_CONFIG_GET(PINCTRL_NODE);

#if TIMER_ADDR == TIM3_BASE

static void tim_init_registers(int freq_kHz)
{
    pinctrl_apply_state(pincfg, PINCTRL_STATE_DEFAULT);

    LL_APB1_GRP1_EnableClock(LL_APB1_GRP1_PERIPH_TIM3);

    // No prescaler --> timer frequency == SystemClock
    TIM3->PSC = 0;

    // Capture/Compare Mode Register 1
    // OCxM = 110: Select PWM mode 1 on OCx
    // OCxPE = 1:  Enable preload register on OCx (reset value)
    TIM3->CCMR2 |= TIM_CCMR2_OC3M_2 | TIM_CCMR2_OC3M_1 | TIM_CCMR2_OC3PE;
    TIM3->CCMR2 |= TIM_CCMR2_OC4M_2 | TIM_CCMR2_OC4M_1 | TIM_CCMR2_OC4PE;

    // Capture/Compare Enable Register
    // CCxP: Active high polarity on OCx (default = 0)
    TIM3->CCER &= ~(TIM_CCER_CC3P); // PB0 / TIM3_CH3: high-side
    TIM3->CCER |= TIM_CCER_CC4P;    // PB1 / TIM3_CH4: low-side

    // Control Register 1
    // TIM_CR1_CMS = 01: Select center-aligned mode 1
    // TIM_CR1_CEN =  1: Counter enable
    TIM3->CR1 |= TIM_CR1_CMS_0 | TIM_CR1_CEN;

    // Force update generation (UG = 1)
    TIM3->EGR |= TIM_EGR_UG;

    // Auto Reload Register
    // center-aligned mode counts up and down in each period, so we need half the clocks as
    // resolution for the given frequency.
    TIM3->ARR = SystemCoreClock / (freq_kHz * 1000) / 2;
}

void half_bridge_start()
{
    if (TIM3->CCR3 != 0U) {
        // Capture/Compare Enable Register
        // CCxE = 1: Enable the output on OCx
        // CCxP = 0: Active high polarity on OCx (default)
        TIM3->CCER |= TIM_CCER_CC3E;
        TIM3->CCER |= TIM_CCER_CC4E;
    }
}

void half_bridge_stop()
{
    TIM3->CCER &= ~(TIM_CCER_CC3E);
    TIM3->CCER &= ~(TIM_CCER_CC4E);
}

uint16_t half_bridge_get_arr()
{
    return TIM3->ARR;
}

uint16_t half_bridge_get_ccr()
{
    return TIM3->CCR3;
}

void half_bridge_set_ccr(uint16_t ccr)
{
    uint16_t ccr_clamped = clamp_ccr(ccr);

    TIM3->CCR3 = ccr_clamped;                 // high-side
    TIM3->CCR4 = ccr_clamped + tim_dt_clocks; // low-side
}

bool half_bridge_enabled()
{
    return TIM3->CCER & TIM_CCER_CC3E;
}

#elif TIMER_ADDR == TIM1_BASE

static void tim_init_registers(int freq_kHz)
{
    pinctrl_apply_state(pincfg, PINCTRL_STATE_DEFAULT);

#ifdef LL_APB2_GRP1_PERIPH_TIM1
    LL_APB2_GRP1_EnableClock(LL_APB2_GRP1_PERIPH_TIM1);
#else
    LL_APB1_GRP2_EnableClock(LL_APB1_GRP2_PERIPH_TIM1);
#endif

    // No prescaler --> timer frequency == SystemClock
    TIM1->PSC = 0;

    // Capture/Compare Mode Register 1
    // OC1M = 110: Select PWM mode 1 on OC1
    // OC1PE = 1:  Enable preload register on OC1 (reset value)
    TIM1->CCMR1 |= TIM_CCMR1_OC1M_2 | TIM_CCMR1_OC1M_1 | TIM_CCMR1_OC1PE;

    // Capture/Compare Enable Register
    // CC1E = 1: Enable the output on OC1
    // CC1P = 0: Active high polarity on OC1 (default)
    // CC1NE = 1: Enable the output on OC1N
    // CC1NP = 0: Active high polarity on OC1N (default)
    TIM1->CCER |= TIM_CCER_CC1E | TIM_CCER_CC1NE;

    // Control Register 1
    // TIM_CR1_CMS = 00: Select edge-aligned mode
    // TIM_CR1_CEN =  1: Counter enable
    TIM1->CR1 |= TIM_CR1_CEN;

#ifdef CONFIG_SOC_SERIES_STM32G4X
    // Boards with STM32G4 MCU use ADC2 for synchronized ADC sampling. We use OC6
    // for triggering, but but don't configure any pin for PWM mode
    TIM1->CCMR3 |= TIM_CCMR3_OC6M_2 | TIM_CCMR3_OC6M_1 | TIM_CCMR3_OC6PE;
    TIM1->CCER |= TIM_CCER_CC6E;
    // Trigger ADC via TIM1_TRGO2 on OC6ref falling edge signal event
    TIM1->CR2 |= TIM_CR2_MMS2_3 | TIM_CR2_MMS2_2 | TIM_CR2_MMS2_0;
#endif

    // Force update generation (UG = 1)
    TIM1->EGR |= TIM_EGR_UG;

    // Auto Reload Register
    // edge-aligned mode possible with TIM1 to increase resolution (no division by 2 necessary)
    TIM1->ARR = SystemCoreClock / (freq_kHz * 1000);

    // Break and Dead-Time Register
    // DTG[7:0]: Dead-time generator setup
    TIM1->BDTR |= (tim_dt_clocks & (uint32_t)0x7F); // ensure that only the last 7 bits are changed

    // Lock Break and Dead-Time Register
    // TODO: does not work properly... maybe HW bug?
    TIM1->BDTR |= TIM_BDTR_LOCK_1 | TIM_BDTR_LOCK_0;
}

void half_bridge_start()
{
    if (TIM1->CCR1 != 0U) {
        // Break and Dead-Time Register
        // MOE  = 1: Main output enable
        TIM1->BDTR |= TIM_BDTR_MOE;
    }
}

void half_bridge_stop()
{
    // Break and Dead-Time Register
    // MOE  = 1: Main output enable
    TIM1->BDTR &= ~(TIM_BDTR_MOE);
}

uint16_t half_bridge_get_arr()
{
    return TIM1->ARR;
}

uint16_t half_bridge_get_ccr()
{
    return TIM1->CCR1;
}

void half_bridge_set_ccr(uint16_t ccr)
{
    TIM1->CCR1 = clamp_ccr(ccr);

#ifdef CONFIG_SOC_SERIES_STM32G4X
    // Trigger ADC for current measurement in the middle of the cycle.
    TIM1->CCR6 = TIM1->CCR1 / 2;
#endif
}

bool half_bridge_enabled()
{
    return TIM1->BDTR & TIM_BDTR_MOE;
}

#elif TIMER_ADDR == HRTIM1_BASE

/*
 * Below initial HRTIM implementation only works for channel A and it does not make use of the
 * possible higher resolution yet.
 */

#include <stm32_ll_bus.h>
#include <stm32_ll_system.h>

static void tim_init_registers(int freq_kHz)
{
    pinctrl_apply_state(pincfg, PINCTRL_STATE_DEFAULT);

    LL_APB2_GRP1_EnableClock(LL_APB2_GRP1_PERIPH_HRTIM1);

    // Enable periodic calibration of delay-locked loop (DLL) with lowest calibration period
    HRTIM1->sCommonRegs.DLLCR |= HRTIM_DLLCR_CALEN | HRTIM_DLLCR_CALRTE_0 | HRTIM_DLLCR_CALRTE_1;

    // Wait for calibration to finish
    while ((HRTIM1_COMMON->ISR & HRTIM_ISR_DLLRDY) == 0) {
    }

    // Prescaler 32 --> SystemClock (same as normal timers like TIM1)
    HRTIM1_TIMA->TIMxCR |= (5U << HRTIM_TIMCR_CK_PSC_Pos);

    // Prescaler 8 / 2^3 --> same frequency as HRTIM
    HRTIM1_TIMA->DTxR |= (3U << HRTIM_DTR_DTPRSC_Pos);

    // Continuous mode operation
    HRTIM1_TIMA->TIMxCR |= HRTIM_TIMCR_CONT;

    // Enable preloading with timer reset update trigger
    // HRTIM1_TIMA->TIMxCR |= HRTIM_TIMCR_PREEN | HRTIM_TIMCR_TRSTU;

    // Enable preloading with timer E update trigger
    // HRTIM1_TIMA->TIMxCR |= HRTIM_TIMCR_PREEN | HRTIM_TIMCR_TEU;

    // Timer period register
    HRTIM1_TIMA->PERxR = SystemCoreClock / (freq_kHz * 1000) + 1;

    HRTIM1_TIMA->SETx1R = HRTIM_SET1R_PER;
    HRTIM1_TIMA->RSTx1R = HRTIM_SET1R_CMP1;

    HRTIM1_TIMA->OUTxR = HRTIM_OUTR_DTEN;

    // Set deadtime values and lock deadtime signs
    HRTIM1_TIMA->DTxR |=
        HRTIM_DTR_DTFSLK | (tim_dt_clocks << 16U) | HRTIM_DTR_DTRSLK | tim_dt_clocks;

    // activate trigger for ADC
    HRTIM1_COMMON->CR1 = HRTIM_CR1_ADC1USRC_0;  // ADC trigger update: Timer A
    HRTIM1_COMMON->ADC1R = HRTIM_ADC1R_AD1TAC3; // ADC trigger event: Timer A compare 3

    // Start timer A
    HRTIM1->sMasterRegs.MCR = HRTIM_MCR_TACEN;
}

void half_bridge_start()
{
    HRTIM1->sCommonRegs.OENR = HRTIM_OENR_TA1OEN | HRTIM_OENR_TA2OEN;
}

void half_bridge_stop()
{
    HRTIM1->sCommonRegs.ODISR = HRTIM_ODISR_TA1ODIS | HRTIM_ODISR_TA2ODIS;
}

uint16_t half_bridge_get_arr()
{
    return HRTIM1_TIMA->PERxR;
}

uint16_t half_bridge_get_ccr()
{
    return HRTIM1_TIMA->CMP1xR;
}

void half_bridge_set_ccr(uint16_t ccr)
{
    HRTIM1_TIMA->CMP1xR = clamp_ccr(ccr);

    // Trigger ADC for current measurement in the middle of the cycle.
    // A negative offset of 80 clocks was found to improve current measurement accuracy and
    // compensate the ADC delay (no risk of underflow as CCR is around 214 even at 0.1% duty).
    HRTIM1_TIMA->CMP3xR = HRTIM1_TIMA->CMP1xR / 2 - 80;
}

bool half_bridge_enabled()
{
    return (HRTIM1->sCommonRegs.OENR & (HRTIM_OENR_TA1OEN | HRTIM_OENR_TA2OEN)) > 0;
}

#endif // HRTIM1

#else // UNIT_TEST

const uint32_t SystemCoreClock = 24000000;

// dummy registers
uint32_t tim_ccr = 0;
uint32_t tim_arr = 0;
bool pwm_enabled = false;

static void tim_init_registers(int freq_kHz)
{
    // assuming edge-aligned PWM like with TIM1
    tim_arr = SystemCoreClock / (freq_kHz * 1000);
}

void half_bridge_start()
{
    pwm_enabled = true;
}

void half_bridge_stop()
{
    pwm_enabled = false;
}

uint16_t half_bridge_get_arr()
{
    return tim_arr;
}

uint16_t half_bridge_get_ccr()
{
    return tim_ccr;
}

void half_bridge_set_ccr(uint16_t ccr)
{
    tim_ccr = clamp_ccr(ccr); // high-side
}

bool half_bridge_enabled()
{
    return pwm_enabled;
}

#endif /* UNIT_TEST */

static void tim_calculate_dt_clocks(int deadtime_ns)
{
    // (clocks per ms * deadtime in ns) / 1000 == (clocks per ms * deadtime in ms)
    // although the C operator precedence does the "right thing" to allow deadtime_ns < 1000 to
    // be handled nicely, parentheses make this more explicit
    tim_dt_clocks = ((SystemCoreClock / (1000000)) * deadtime_ns) / 1000;
}

void half_bridge_init(int freq_kHz, int deadtime_ns, float min_duty, float max_duty)
{
    tim_calculate_dt_clocks(deadtime_ns);

    tim_init_registers(freq_kHz);

    tim_ccr_min = min_duty * half_bridge_get_arr();
    tim_ccr_max = max_duty * half_bridge_get_arr();

    half_bridge_set_duty_cycle(max_duty); // init with allowed value
}

void half_bridge_set_duty_cycle(float duty)
{
    if (duty >= 0.0f && duty <= 1.0f) {
        half_bridge_set_ccr(half_bridge_get_arr() * duty);
    }
}

float half_bridge_get_duty_cycle()
{
    return (float)(half_bridge_get_ccr()) / half_bridge_get_arr();
}

#endif // BOARD_HAS_DCDC
```
